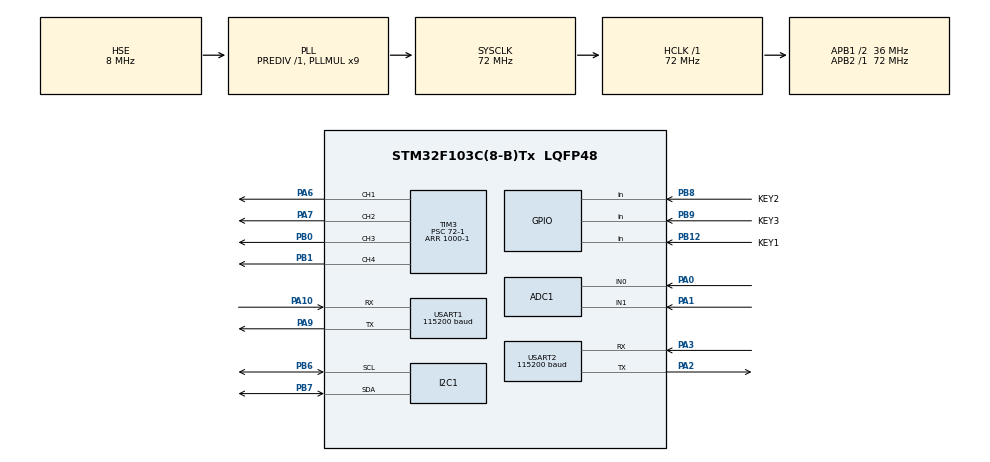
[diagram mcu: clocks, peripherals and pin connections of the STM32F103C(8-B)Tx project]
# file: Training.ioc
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ADC1.Channel-0\#ChannelRegularConversion=ADC_CHANNEL_0
ADC1.Channel-1\#ChannelRegularConversion=ADC_CHANNEL_1
ADC1.ContinuousConvMode=DISABLE
ADC1.NbrOfConversion=2
ADC1.NbrOfConversionFlag=1
ADC1.Rank-0\#ChannelRegularConversion=1
ADC1.Rank-1\#ChannelRegularConversion=2
ADC1.SamplingTime-0\#ChannelRegularConversion=ADC_SAMPLETIME_239CYCLES_5
ADC1.SamplingTime-1\#ChannelRegularConversion=ADC_SAMPLETIME_239CYCLES_5
ADC1.ScanConvMode=ENABLE
ADC1.master=1
Mcu.Family=STM32F1
Mcu.Name=STM32F103C(8-B)Tx
Mcu.Package=LQFP48
NVIC.PriorityGroup=NVIC_PRIORITYGROUP_4
PA0-WKUP.Signal=ADCx_IN0
PA1.Signal=ADCx_IN1
PA10.Mode=Asynchronous
PA10.Signal=USART1_RX
PA13.Mode=Serial_Wire
PA13.Signal=SYS_JTMS-SWDIO
PA14.Mode=Serial_Wire
PA14.Signal=SYS_JTCK-SWCLK
PA2.Mode=Asynchronous
PA2.Signal=USART2_TX
PA3.Mode=Asynchronous
PA3.Signal=USART2_RX
PA6.Signal=S_TIM3_CH1
PA7.Signal=S_TIM3_CH2
PA9.Mode=Asynchronous
PA9.Signal=USART1_TX
PB0.Signal=S_TIM3_CH3
PB1.Signal=S_TIM3_CH4
PB12.GPIO_Label=KEY1
PB12.GPIO_PuPd=GPIO_PULLUP
PB12.Signal=GPIO_Input
PB6.GPIO_Pu=GPIO_PULLUP
PB6.Mode=I2C
PB6.Signal=I2C1_SCL
PB7.GPIO_Pu=GPIO_PULLUP
PB7.Mode=I2C
PB7.Signal=I2C1_SDA
PB8.GPIO_Label=KEY2
PB8.GPIO_PuPd=GPIO_PULLUP
PB8.Signal=GPIO_Input
PB9.GPIO_Label=KEY3
PB9.GPIO_PuPd=GPIO_PULLUP
PB9.Signal=GPIO_Input
PD0-OSC_IN.Mode=HSE-External-Oscillator
PD0-OSC_IN.Signal=RCC_OSC_IN
PD1-OSC_OUT.Mode=HSE-External-Oscillator
PD1-OSC_OUT.Signal=RCC_OSC_OUT
ProjectManager.HeapSize=0x800
ProjectManager.StackSize=0x400
ProjectManager.TargetToolchain=MDK-ARM V5.32
RCC.ADCPresc=RCC_ADCPCLK2_DIV6
RCC.AHBFreq_Value=72000000
RCC.APB1CLKDivider=RCC_HCLK_DIV2
RCC.APB1Freq_Value=36000000
RCC.APB1TimFreq_Value=72000000
RCC.APB2Freq_Value=72000000
RCC.APB2TimFreq_Value=72000000
RCC.HCLKFreq_Value=72000000
RCC.LSE_VALUE=32768
RCC.PLLMUL=RCC_PLL_MUL9
RCC.PLLSourceVirtual=RCC_PLLSOURCE_HSE
RCC.SYSCLKFreq_VALUE=72000000
RCC.SYSCLKSource=RCC_SYSCLKSOURCE_PLLCLK
RCC.USBFreq_Value=72000000
RTC.Date=22
RTC.Hours=19
RTC.Minutes=0
RTC.Month=RTC_MONTH_SEPTEMBER
RTC.Seconds=0
RTC.WeekDay=RTC_WEEKDAY_TUESDAY
RTC.Year=26
SH.ADCx_IN0.0=ADC1_IN0,IN0
SH.ADCx_IN1.0=ADC1_IN1,IN1
SH.S_TIM3_CH1.0=TIM3_CH1,PWM Generation1 CH1
SH.S_TIM3_CH2.0=TIM3_CH2,PWM Generation2 CH2
SH.S_TIM3_CH3.0=TIM3_CH3,PWM Generation3 CH3
SH.S_TIM3_CH4.0=TIM3_CH4,PWM Generation4 CH4
TIM3.Channel-PWM\ Generation1\ CH1=TIM_CHANNEL_1
TIM3.Channel-PWM\ Generation2\ CH2=TIM_CHANNEL_2
TIM3.Channel-PWM\ Generation3\ CH3=TIM_CHANNEL_3
TIM3.Channel-PWM\ Generation4\ CH4=TIM_CHANNEL_4
TIM3.Period=1000-1
TIM3.Prescaler=72-1
TIM3.Pulse-PWM\ Generation1\ CH1=0
TIM3.Pulse-PWM\ Generation2\ CH2=0
TIM3.Pulse-PWM\ Generation3\ CH3=0
TIM3.Pulse-PWM\ Generation4\ CH4=0
USART1.BaudRate=115200
USART1.VirtualMode=VM_ASYNC
USART2.BaudRate=115200
USART2.VirtualMode=VM_ASYNC
VP_RTC_VS_RTC_Activate.Mode=RTC_Enabled
VP_RTC_VS_RTC_Calendar.Mode=RTC_Calendar
VP_TIM3_VS_ClockSourceINT.Mode=Internal
board=custom

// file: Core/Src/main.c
/* USER CODE BEGIN Header */
/**
  ******************************************************************************
  * @file           : main.c
  * @brief          : Main program body
  ******************************************************************************
  * @attention
  *
  * Copyright (c) 2026 STMicroelectronics.
  * All rights reserved.
  *
  * This software is licensed under terms that can be found in the LICENSE file
  * in the root directory of this software component.
  * If no LICENSE file comes with this software, it is provided AS-IS.
  *
  ******************************************************************************
  */
/* USER CODE END Header */
#include "main.h"
#include "adc.h"
#include "i2c.h"
#include "rtc.h"
#include "tim.h"
#include "usart.h"
#include "gpio.h"

/* USER CODE BEGIN Includes */
  #include "app_main.h"

/* USER CODE END Includes */

void SystemClock_Config(void);

int main(void)
{

  /* MCU Configuration--------------------------------------------------------*/

  /* Reset of all peripherals, Initializes the Flash interface and the Systick. */
  HAL_Init();

  /* Configure the system clock */
  SystemClock_Config();

  /* Initialize all configured peripherals */
  MX_GPIO_Init();
  MX_ADC1_Init();
  MX_I2C1_Init();
  MX_RTC_Init();
  MX_USART1_UART_Init();
  MX_USART2_UART_Init();
  MX_TIM3_Init();
  /* USER CODE BEGIN 2 */
  APP_Main_Init();

  /* USER CODE END 2 */

  /* Infinite loop */
  /* USER CODE BEGIN WHILE */
  while (1)
  {
    APP_Main_Process();
    /* USER CODE END WHILE */

  }
}

void SystemClock_Config(void)
{
  RCC_OscInitTypeDef RCC_OscInitStruct = {0};
  RCC_ClkInitTypeDef RCC_ClkInitStruct = {0};
  RCC_PeriphCLKInitTypeDef PeriphClkInit = {0};

  /** Initializes the RCC Oscillators according to the specified parameters
  * in the RCC_OscInitTypeDef structure.
  */
  RCC_OscInitStruct.OscillatorType = RCC_OSCILLATORTYPE_LSI|RCC_OSCILLATORTYPE_HSE;
  RCC_OscInitStruct.HSEState = RCC_HSE_ON;
  RCC_OscInitStruct.HSEPredivValue = RCC_HSE_PREDIV_DIV1;
  RCC_OscInitStruct.HSIState = RCC_HSI_ON;
  RCC_OscInitStruct.LSIState = RCC_LSI_ON;
  RCC_OscInitStruct.PLL.PLLState = RCC_PLL_ON;
  RCC_OscInitStruct.PLL.PLLSource = RCC_PLLSOURCE_HSE;
  RCC_OscInitStruct.PLL.PLLMUL = RCC_PLL_MUL9;
  if (HAL_RCC_OscConfig(&RCC_OscInitStruct) != HAL_OK)
  {
    Error_Handler();
  }

  /** Initializes the CPU, AHB and APB buses clocks
  */
  RCC_ClkInitStruct.ClockType = RCC_CLOCKTYPE_HCLK|RCC_CLOCKTYPE_SYSCLK
                              |RCC_CLOCKTYPE_PCLK1|RCC_CLOCKTYPE_PCLK2;
  RCC_ClkInitStruct.SYSCLKSource = RCC_SYSCLKSOURCE_PLLCLK;
  RCC_ClkInitStruct.AHBCLKDivider = RCC_SYSCLK_DIV1;
  RCC_ClkInitStruct.APB1CLKDivider = RCC_HCLK_DIV2;
  RCC_ClkInitStruct.APB2CLKDivider = RCC_HCLK_DIV1;

  if (HAL_RCC_ClockConfig(&RCC_ClkInitStruct, FLASH_LATENCY_2) != HAL_OK)
  {
    Error_Handler();
  }
  PeriphClkInit.PeriphClockSelection = RCC_PERIPHCLK_RTC|RCC_PERIPHCLK_ADC;
  PeriphClkInit.RTCClockSelection = RCC_RTCCLKSOURCE_LSI;
  PeriphClkInit.AdcClockSelection = RCC_ADCPCLK2_DIV6;
  if (HAL_RCCEx_PeriphCLKConfig(&PeriphClkInit) != HAL_OK)
  {
    Error_Handler();
  }
}

void Error_Handler(void)
{
  __disable_irq();
  while (1)
  {
  }
}
